# ATA5700M322 device description
Architecture: AVR8; Family: megaAVR
Registers are 8-bit, access not given, no defined reset value unless marked. A register's access mark holds for its fields unless they carry their own. Offsets are from the block's base; [hi:lo] are bit positions; {n}, {i} and the like mark numbered series; 'fields as' and 'values as' point back to an identical list.

## SPI
Instances: SPI 0x00
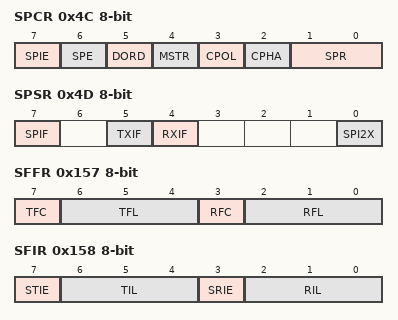
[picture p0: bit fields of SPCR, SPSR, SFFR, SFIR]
0x4C SPCR — SPI control Register
  [7] SPIE — Spe Interrupt Enable
  [6] SPE — SPI Enable
  [5] DORD — Data Order
  [4] MSTR — Master/Slave Select
  [3] CPOL — Clock Polarity
  [2] CPHA — Clock Phase
  [1:0] SPR — SPI Clock Rate Select
    0=clkio/4; 1=clkio/16; 2=clkio/64; 3=clkio/128
0x4D SPSR — SPI Status Register
  [7] SPIF — SPI Interrupt Flag
  [5] TXIF — Tx Buffer Interrupt Flag
  [4] RXIF — Rx Buffer Interrupt Flag
  [0] SPI2X — Double SPI Speed Bit
0x4E SPDR — SPI Data Register
0x157 SFFR — SPI FIFO Fill Status Register
  [7] TFC — SPI Tx Buffer Clear
  [6:4] TFL — Transmit Buffer Fill Level
  [3] RFC — Rx Buffer Clear
  [2:0] RFL — Receive Buffer Fill Level
0x158 SFIR — SPI FIFO Interrupt Register
  [7] STIE — SPI Rx Buffer Interrupt Enable
  [6:4] TIL — Transmit Buffer Interrupt Level
  [3] SRIE — Rx Buffer Interrupt Enable
  [2:0] RIL — Receive Buffer Interrupt Level

## SPI2
Instances: SPI2 0x00
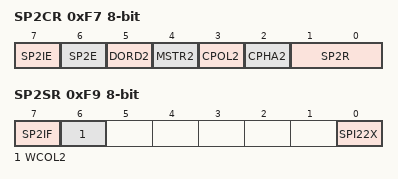
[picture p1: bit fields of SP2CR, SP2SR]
0xF7 SP2CR — SPI2 control Register
  [7] SP2IE — Spi2 Interrupt Enable
  [6] SP2E — SPI2 Enable
  [5] DORD2 — Data Order
  [4] MSTR2 — Master/Slave Select
  [3] CPOL2 — Clock Polarity
  [2] CPHA2 — Clock Phase
  [1:0] SP2R — SPI2 Clock Rate Select
    0=clkio/4; 1=clkio/16; 2=clkio/64; 3=clkio/128
0xF8 SP2DR — SPI2 Data Register
0xF9 SP2SR — SPI2 Status Register
  [7] SP2IF — SPI2 Interrupt Flag
  [6] WCOL2 — Write Colliion Flag
  [0] SPI22X — Double SPI2 Speed Bit

## SSM
Instances: SSM 0x00
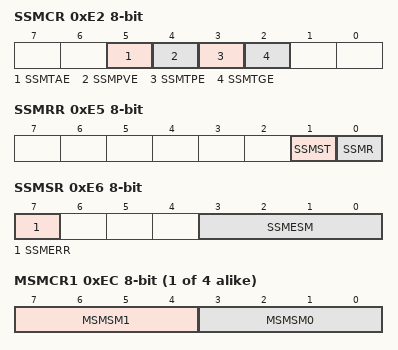
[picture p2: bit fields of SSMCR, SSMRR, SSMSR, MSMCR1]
0xE2 SSMCR — SSM Control Register
  [5] SSMTAE — Sequencer State Machine Tx Ask-Shaping Enable
  [4] SSMPVE — Sequencer State Machine PV Enable
  [3] SSMTPE — Sequencer State Machine Tx Preemphasis Enable
  [2] SSMTGE — Sequencer State Machine Tx Gauss Enable
0xE4 SSMFBR — SSM Filter Bandwidth Register
  [5] SSMPLDT — Sequencer State Machine PLL Lock Delay Time
0xE5 SSMRR — SSM Run Register
  [1] SSMST — Sequencer State Machine Stop
  [0] SSMR — Sequencer State Machine Run
0xE6 SSMSR — SSM Status Register
  [7] SSMERR — Sequencer State Machine Error
  [3:0] SSMESM — Sequencer State Machine Error State Machine
0xE7 SSMIFR — SSM Interrupt Flag Register
  [0] SSMIF — Sequencer State Machine Interrupt Flag
0xE8 SSMIMR — SSM interrupt mask register
  [0] SSMIM — Sequencer State Machine Interrupt Mask
0xE9 MSMSTR — Master State Machine state register
  [4:0] SSMMST — Sequencer State Machine Master State
0xEA SSMSTR — SSM State Register
  [5:0] SSMSTA — Sequencer State Machine State A
{0xEB+i} MSMCR{i} (i=1..4) — Master State Machine Control Register {i}
  [7:4] MSMSM{2i-1} — Master State Machine SubState Machine Select {2i-1}
    0=None/Stop; 1=PLL en; 2=PLL lock; 3=TX DSP enable; 4=TX DSP disable; 5=Send telegram; 6=Shut down; 7=VCO Tuning; 8=Antenna Tuning
  [3:0] MSMSM{2i-2} — Master State Machine SubState Machine Select {2i-2}
    values as MSMSM{2i-1}

## SUP
Instances: SUP 0x00
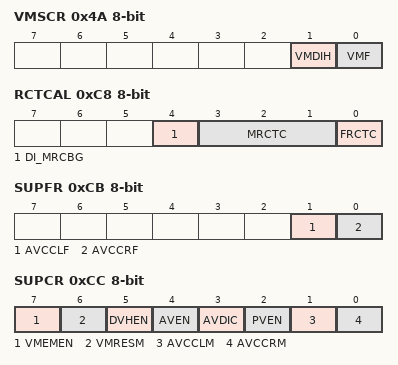
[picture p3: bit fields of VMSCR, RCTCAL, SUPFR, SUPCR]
0x4A VMSCR — Voltage Monitor Status and Control Register
  [1] VMDIH — Voltage Monitor Disable Hysteresis
  [0] VMF — Voltage Monitor Flag
0xC8 RCTCAL — RC oscillator Temperature Compensation register
  [4] DI_MRCBG — Disable MRC Oscillator Bandgap
  [3:1] MRCTC — Medium frequency RC Oscillator Temperature Compensation
  [0] FRCTC — FRC Oscillator Temperature Compensation bit
0xCB SUPFR — Supply Interrupt Flag Register
  [1] AVCCLF — AVCC low interrupt flag
  [0] AVCCRF — AVCC reset interrupt flag
0xCC SUPCR — Supply Control Register
  [7] VMEMEN — Memory Voltage Regulator Enable
  [6] VMRESM — VMEM Reset Mask
  [5] DVHEN — DVCC High Current Mode Enable
  [4] AVEN — AVCC Enable
  [3] AVDIC — AVCC Double Internal Current
  [2] PVEN — Power amplifier Voltage supply Enable
  [1] AVCCLM — AVCC Low Interrupt Mask
  [0] AVCCRM — AVCC Reset Interrupt Mask
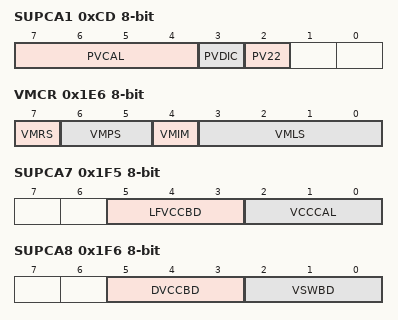
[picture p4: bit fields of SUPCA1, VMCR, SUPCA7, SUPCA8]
0xCD SUPCA1 — Supply calibration register 1
  [7:4] PVCAL — Power Amplifier Regulator Calibration
  [3] PVDIC — Power Amplifier Regulator Double Internal Current
  [2] PV22 — Power Amplifier Voltage 2.2V
0xCE SUPCA2 — Supply calibration register 2
  [3:0] BGCAL — Band Gap Calibration
0xCF SUPCA3 — Supply calibration register 3
  [7:0] ACAL — AVCC Regulator Output Voltage Calibration
0xD0 SUPCA4 — Supply calibration register 4
  [5:0] ICONST — ICONST Constant current of bandgap
0xD1 CALRDY — Calibration ready signature
0x1E6 VMCR — Voltage Monitor Control Register
  [7] VMRS — Voltage Monitor Range Select
  [6:5] VMPS — Voltage Monitor Power Supply Select
  [4] VMIM — Voltage Monitor Interrupt Mask
  [3:0] VMLS — Voltage Monitor Level Select
0x1E8 CALRDYLF — Calibration ready signature LFVCC
0x1F3 SUPCA5 — Supply calibration register 5
  [5:0] IPTAT — IPTAT current of bandgap
0x1F4 SUPCA6 — Supply calibration register 6
  [7:0] VBGTR — Threshold voltage of bandgap
0x1F5 SUPCA7 — Supply calibration register 7
  [5:3] LFVCCBD — VREF voltage for LFVCC Brown-out-Detector
  [2:0] VCCCAL — LFVCC and DVCC Output Voltage Calibration
0x1F6 SUPCA8 — Supply calibration register 8
  [5:3] DVCCBD — VREF voltage for DVCC Brown-out-Detector
  [2:0] VSWBD — VSIG voltage for LFVCC Brown-out-Detector
0x1F7 SUPCA9 — Supply calibration register 9
  [7:0] VMEM — VMEM ldo voltage
0x1F8 SUPCA10 bits used 4:0 — Supply calibration register 10
0x1FE PMTER — Power Management Test Enable Register
